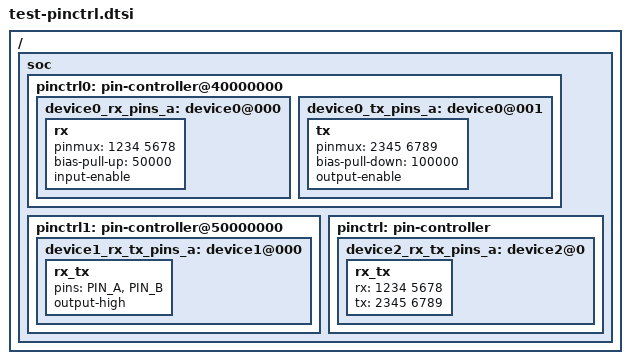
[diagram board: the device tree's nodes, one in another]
/*
 * Copyright (c) 2017 b0661n0e17e@gmail.com
 *
 * SPDX-License-Identifier: Apache-2.0
 */

#include "test-pinctrl.h"

/ {
	soc {
		pinctrl0: pin-controller@40000000 {
                        device0_rx_pins_a: device0@000 {
                                rx {
                                        pinmux = <1234 5678>;
                                        bias-pull-up = <50000>;
                                        input-enable;
                                };
                        };
                        device0_tx_pins_a: device0@001 {
                                tx {
                                        pinmux = <2345 6789>;
                                        bias-pull-down = <100000>;
                                        output-enable;
                                };
                        };
		};
		pinctrl1: pin-controller@50000000 {
                        device1_rx_tx_pins_a: device1@000 {
                                rx_tx {
                                        pins = "PIN_A", "PIN_B";
                                        output-high;
                                };
                        };
		};
		pinctrl: pin-controller {
			device2_rx_tx_pins_a: device2@0 {
				rx_tx {
					rx = <1234 5678>;
					tx = <2345 6789>;
				};
			};
                };
	};
};
